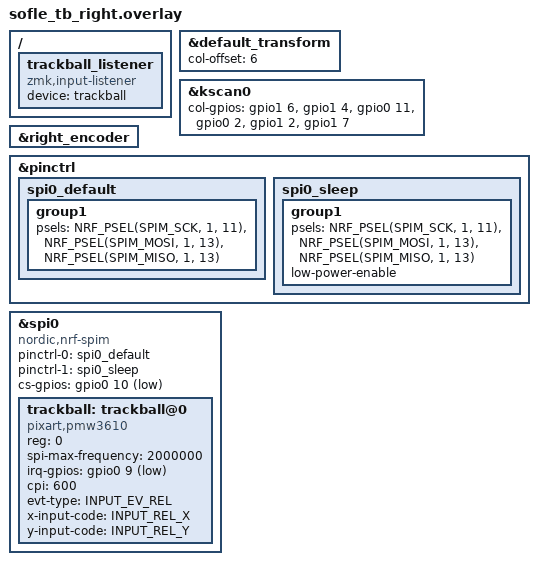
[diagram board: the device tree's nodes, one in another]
/*
 * Copyright (c) 2020 Ryan Cross
 *
 * SPDX-License-Identifier: MIT
 */

#include "sofle_tb.dtsi"

&default_transform {
    col-offset = <6>;
};

&kscan0 {
    col-gpios
        = <&gpio1 6 GPIO_ACTIVE_HIGH>
        , <&gpio1 4 GPIO_ACTIVE_HIGH>
        , <&gpio0 11 GPIO_ACTIVE_HIGH>
        , <&gpio0 2 GPIO_ACTIVE_HIGH>
        , <&gpio1 2 GPIO_ACTIVE_HIGH>
        , <&gpio1 7 GPIO_ACTIVE_HIGH>
        ;
};

&right_encoder {
    status = "okay";
};

&pinctrl {
    spi0_default: spi0_default {
        group1 {
            psels = <NRF_PSEL(SPIM_SCK, 1, 11)>,
                <NRF_PSEL(SPIM_MOSI, 1, 13)>,
                <NRF_PSEL(SPIM_MISO, 1, 13)>;
        };
    };

    spi0_sleep: spi0_sleep {
        group1 {
            psels = <NRF_PSEL(SPIM_SCK, 1, 11)>,
                <NRF_PSEL(SPIM_MOSI, 1, 13)>,
                <NRF_PSEL(SPIM_MISO, 1, 13)>;
            low-power-enable;
        };
    };
};

&spi0 {
    status = "okay";
    compatible = "nordic,nrf-spim";
    pinctrl-0 = <&spi0_default>;
    pinctrl-1 = <&spi0_sleep>;
    pinctrl-names = "default", "sleep";
    cs-gpios = <&gpio0 10 GPIO_ACTIVE_LOW>;

    trackball: trackball@0 {
        status = "okay";
        compatible = "pixart,pmw3610";
        reg = <0>;
        spi-max-frequency = <2000000>;
        irq-gpios = <&gpio0 9 (GPIO_ACTIVE_LOW | GPIO_PULL_UP)>;
        cpi = <600>;
        evt-type = <INPUT_EV_REL>;
        x-input-code = <INPUT_REL_X>;
        y-input-code = <INPUT_REL_Y>;
    };
};

/ {
  trackball_listener {
    compatible = "zmk,input-listener";
    device = <&trackball>;

  };
};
